# GD32H71x_72x register map
File version: 1.0
CPU: CM7 r1p2, little endian, MPU, FPU, 4 interrupt priority bits
Registers are 32-bit, read-write, reset 0x0 unless marked. A register's access mark holds for its fields unless they carry their own. Offsets are from the block's base; [hi:lo] are bit positions; {n}, {i} and the like mark numbered series.

## SSI0 — Synchronous Serial Interface module
Base 0x4000DC00
Same registers: SSI1 0x40002800
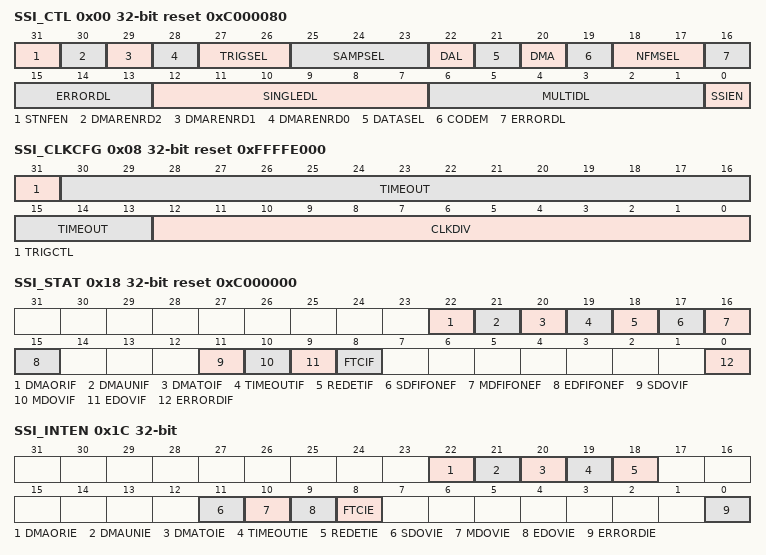
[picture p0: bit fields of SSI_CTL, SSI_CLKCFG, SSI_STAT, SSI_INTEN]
0x00 SSI_CTL reset 0xC000080 — SSI control register
  [31] STNFEN — Start the next frame enable
  [30] DMARENRD2 — DMA read enable for EDIM_SSI_RDATA2
  [29] DMARENRD1 — DMA read enable for EDIM_SSI_RDATA1
  [28] DMARENRD0 — DMA read enable for EDIM_SSI_RDATA0
  [27:26] TRIGSEL — SSI trigger selection
  [25:23] SAMPSEL — Sampling point selection
  [22] DAL — Data alignment
  [21] DATASEL — Select whether singleturn and multiturn data are stored in the same register.
  [20] DMA — DMA request enable
  [19] CODEM — The coding mode of the received data
  [18:17] NFMSEL — Noise filter mode selection
  [16:13] ERRORDL — Error data length
  [12:7] SINGLEDL — Singleturn data length
  [6:1] MULTIDL — Multiturn data length
  [0] SSIEN — SSI enable
0x04 SSI_CLKINT — SSI clock interval register
  [31:0] CLKINT — SSI clock sequence interval time
0x08 SSI_CLKCFG reset 0xFFFFE000 — SSI clock configure register
  [31] TRIGCTL — SSI trigger control
  [30:13] TIMEOUT — Timeout time
  [12:0] CLKDIV — Clock division
0x0C SSI_RDATA0 — SSI received data register0
  [31:0] MULTIDATA — 32-bit multiturn data
0x10 SSI_RDATA1 — SSI received data register 1
  [31:0] SINGLEDATA — 32-bit singleturn data
0x14 SSI_RDATA2 — SSI received data register 2
  [7:0] ERRORDATA — 8-bit error data
0x18 SSI_STAT access per field reset 0xC000000 — SSI status register
  [22] DMAORIF rw — DMA overrun interrupt flag
  [21] DMAUNIF rw — DMA underrun interrupt flag
  [20] DMATOIF rw — DMA timeout interrupt flag
  [19] TIMEOUTIF rw — Timeout interrupt flag
  [18] REDETIF rw — Rising edge detection interrupt flag
  [17] SDFIFONEF ro — Singleturn FIFO non-empty flag
  [16] MDFIFONEF ro — Multiturn FIFO non-empty flag
  [15] EDFIFONEF ro — Error FIFO non-empty flag
  [11] SDOVIF rw — Singleturn data overflow interrupt flag
  [10] MDOVIF rw — Multiturn data overflow interrupt flag
  [9] EDOVIF rw — Error data overflow interrupt flag
  [8] FTCIF rw — Frame transmission completion interrupt flag
  [0] ERRORDIF rw — Error data interrupt flag
0x1C SSI_INTEN — SSI interrupt enable register
  [22] DMAORIE — DMA overrun interrupt enable
  [21] DMAUNIE — DMA underrun interrupt enable
  [20] DMATOIE — DMA timeout interrupt enable
  [19] TIMEOUTIE — Timeout interrupt enable
  [18] REDETIE — Rising edge detection interrupt enable
  [11] SDOVIE — Singleturn data overflow interrupt enable
  [10] MDOVIE — Multiturn data overflow interrupt enable
  [9] EDOVIE — Error data overflow interrupt enable
  [8] FTCIE — Frame transmission completion interrupt enable
  [0] ERRORDIE — Error data interrupt enable
0x20 SSI_SWT wo — SSI software trigger register
  [0] SWTRIG — Software trigger
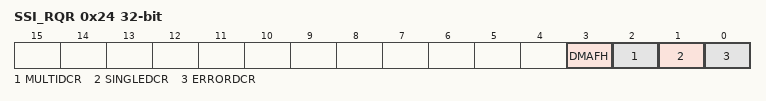
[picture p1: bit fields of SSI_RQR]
0x24 SSI_RQR wo — SSI request register
  [3] DMAFH — DMA interface flush
  [2] MULTIDCR — Multiturn data clear request
  [1] SINGLEDCR — Singleturn data clear request
  [0] ERRORDCR — Error data clear request
0x100 SSI_DMARDATA ro reset 0xC000000 — SSI DMA read data register
  [31:0] DMARDATA — DMA read data from this register

## TFMT0 — Tamagawa format encoder interface module
Base 0x4000C800
Same registers: TFMT1 0x40001C00
0x00 DATAID — TFMT ID code register
  [3:0] CC — Data ID code
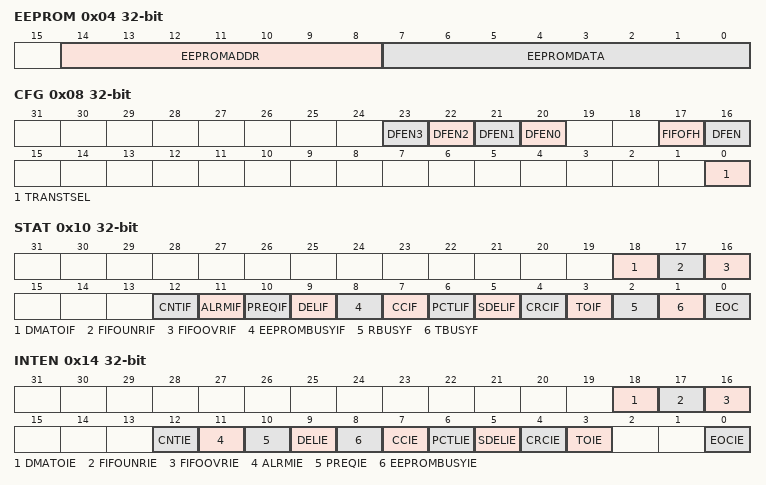
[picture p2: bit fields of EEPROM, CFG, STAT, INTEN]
0x04 EEPROM — TFMT EEPROM register
  [14:8] EEPROMADDR — EEPROM accessing address of encoder
  [7:0] EEPROMDATA — Data to be written into EEPROM of encoder
0x08 CFG access per field — TFMT configuration register
  [n+20] DFEN{n} rw (n=0..3) — DMA request and FIFO enable for EDIM_TFMT_RDATA{n} register
  [17] FIFOFH wo — FIFO flush
  [16] DFEN rw — DMA request and FIFO enable
  [0] TRANSTSEL rw — Transmission start trigger selection
0x0C SWT wo — TFMT software trigger register
  [0] SWTR — Data transmission software trigger, cleared by hardware
0x10 STAT — TFMT status register
  [18] DMATOIF — DMA request timeout error interrupt flag
  [17] FIFOUNRIF — FIFO underrun error interrupt flag
  [16] FIFOOVRIF — FIFO overrun error interrupt flag
  [12] CNTIF — Counting error interrupt flag of encoder
  [11] ALRMIF — Alarm interrupt flag of encoder
  [10] PREQIF — Parity error interrupt flag in request frame
  [9] DELIF — Delimiter error interrupt flag in request frame
  [8] EEPROMBUSYIF — EEPROM busy interrupt flag
  [7] CCIF — Data ID code error interrupt flag
  [6] PCTLIF — Parity error interrupt flag in received control field of frame
  [5] SDELIF — Start bit error interrupt flag or delimiter error flag in received frame
  [4] CRCIF — CRC error interrupt flag in received frame
  [3] TOIF — Encoder transmission timeout error interrupt flag
  [2] RBUSYF — Receive busy flag
  [1] TBUSYF — Transmit busy flag
  [0] EOC — End of communication
0x14 INTEN — TFMT interrupt enable register
  [18] DMATOIE — Interrupt enable of DMATOIF
  [17] FIFOUNRIE — Interrupt enable of FIFOUNRIF
  [16] FIFOOVRIE — Interrupt enable of FIFOOVRIF
  [12] CNTIE — Interrupt enable for CNTIF
  [11] ALRMIE — Interrupt enable for ALRMIF
  [10] PREQIE — Interrupt enable for PREQIF
  [9] DELIE — Interrupt enable for DELIF
  [8] EEPROMBUSYIE — Interrupt enable for EEPROMBUSYIF
  [7] CCIE — Interrupt enable for CCIF
  [6] PCTLIE — Interrupt enable for PCTLIF
  [5] SDELIE — Interrupt enable for SDELIF
  [4] CRCIE — Interrupt enable for CRCIF
  [3] TOIE — Interrupt enable for TOIF
  [0] EOCIE — Interrupt enable for EOC
{0x18+4i} RDATA{i} ro (i=0..3) — TFMT received data register {i}
  [31:0] RDATA — Received data from encoder
0x128 FIFODATA ro — TFMT FIFO data register
  [31:0] FIFODATA — FIFO data from EDIM_TFMT_RDATAx registers
0x200 STATUCTL — TFMT status update control register
  [0] STATUPMODE — Encoder status update mode
